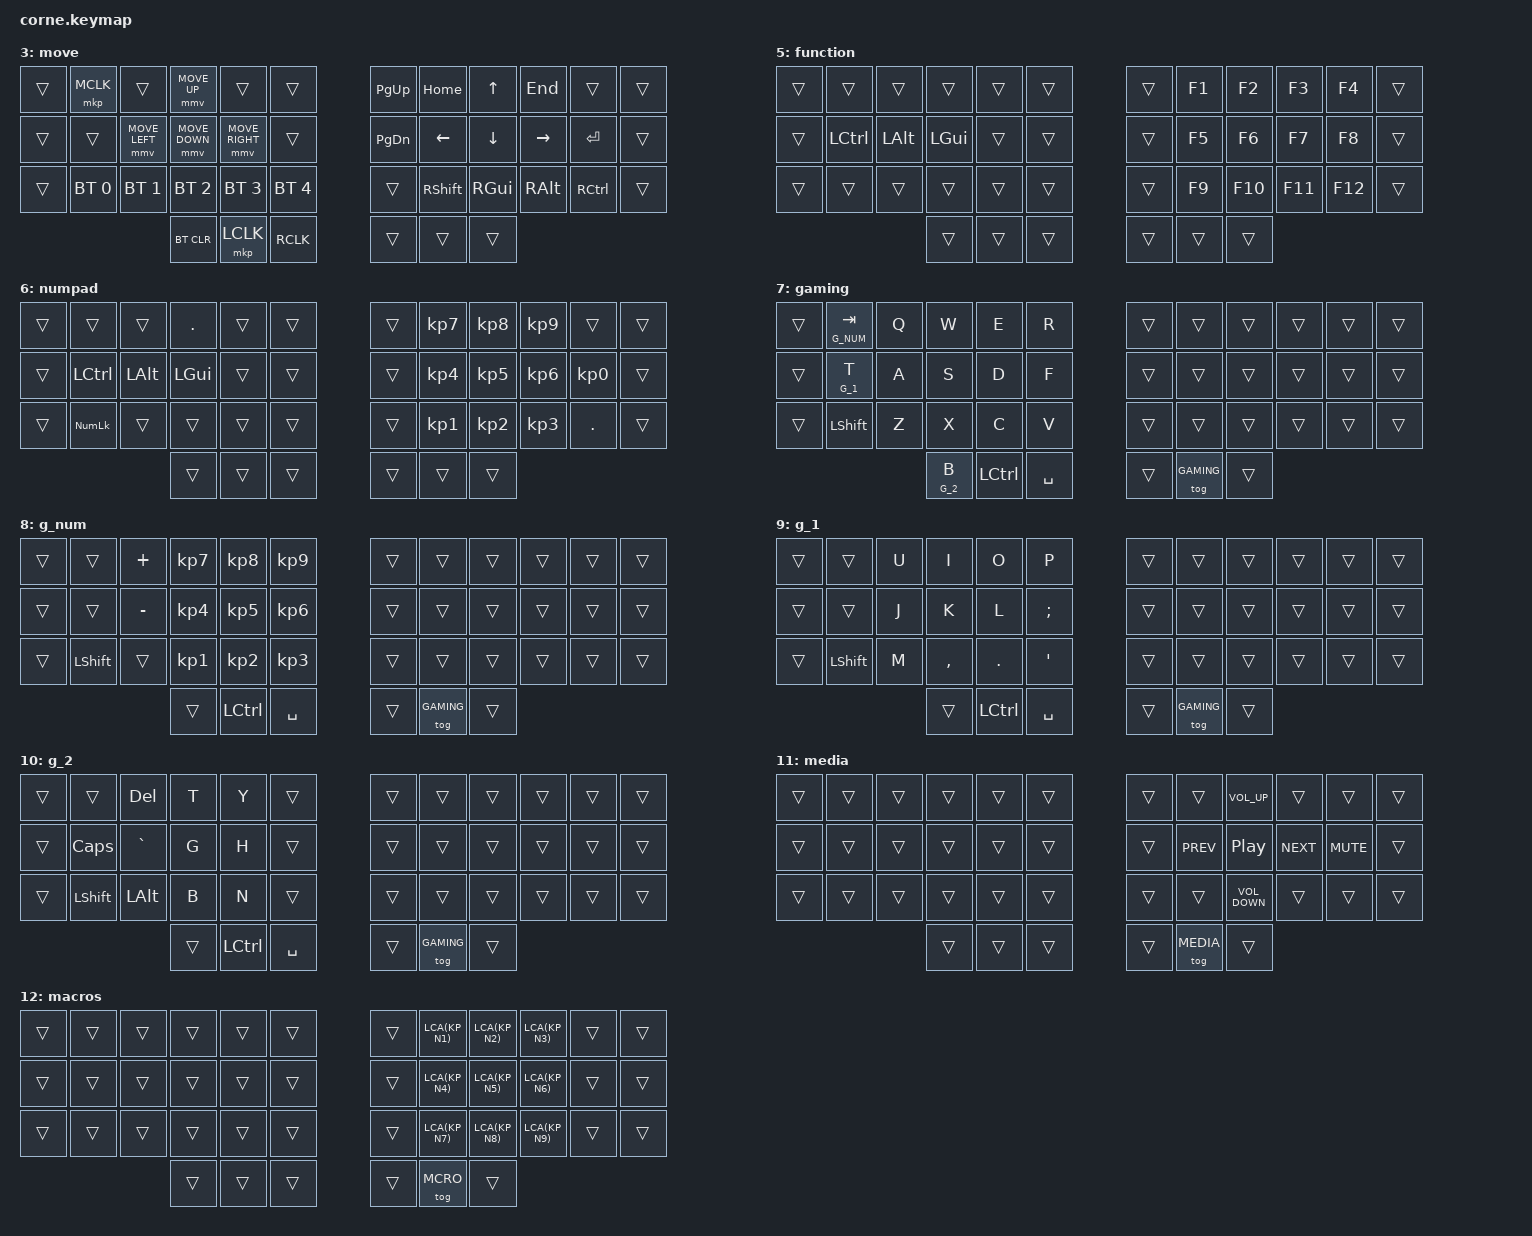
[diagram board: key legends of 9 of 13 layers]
/*
 * Copyright (c) 2020 The ZMK Contributors
 *
 * SPDX-License-Identifier: MIT
 */

#include <behaviors.dtsi>
#include <dt-bindings/zmk/keys.h>
#include <dt-bindings/zmk/bt.h>
#include <dt-bindings/zmk/mouse.h>
/* #include <stdio.h> */
#include "includes/helper.h"
#include "includes/keypos_42keys.h"

#define ___ &trans

// homerow mods
ZMK_BEHAVIOR(hrm, hold_tap,
    flavor = "balanced";
    tapping-term-ms = <280>;
    quick-tap-ms = <125>;
    global-quick-tap;
    bindings = <&kp>, <&kp>;
)

#define LCA(KEY) &kp LC(LA(KEY))

/* Define home row mods */
#define HLC &hrm LCTRL
#define HRC &hrm RCTRL
#define HLA &hrm LALT
#define HRA &hrm RALT
#define HLG &hrm LGUI
#define HRG &hrm RGUI

/* Define shorter mouse keys */
#define MUP &mmv MOVE_UP
#define MDN &mmv MOVE_DOWN
#define MLT &mmv MOVE_LEFT
#define MRT &mmv MOVE_RIGHT
/* clicks */
#define MLC &mkp LCLK
#define MMC &mkp MCLK
#define MRC &kp RCLK

/* Define media controls */ 
#define VUP &kp C_VOLUME_UP
#define VDN &kp C_VOLUME_DOWN
#define VMT &kp C_MUTE
#define PLAY &kp C_PLAY_PAUSE
#define NEXT &kp C_NEXT
#define PREV &kp C_PREV



/*                                      42 KEY MATRIX / LAYOUT MAPPING

  ╭────────────────────────┬────────────────────────╮ ╭─────────────────────────┬─────────────────────────╮
  │ --   1   2   3   4   5 │  6   7   8   9  10  -- │ │ --- LT4 LT3 LT2 LT1 LT0 │ RT0 RT1 RT2 RT3 RT4 --- │
  │ --  13  14  15  16  17 │ 18  19  20  21  22  -- │ │ --- LM4 LM3 LM2 LM1 LM0 │ RM0 RM1 RM2 RM3 RM4 --- │
  │ --  25  26  27  28  29 │ 30  31  32  33  34  -- │ │ --- LB4 LB3 LB2 LB1 LB0 │ RB0 RB1 RB2 RB3 RB4 --- │
  ╰───────────╮ 36  37  38 │ 39  40  41 ╭───────────╯ ╰───────────╮ LH2 LH1 LH0 │ RH0 RH1 RH2 ╭───────────╯
              ╰────────────┴────────────╯                         ╰─────────────┴─────────────╯             */

// layer shortcuts, must match order in which they are defined below
#define DVORAK 0
#define SNTH 1
#define HANDS 2
#define MOV 3
#define SYM 4
#define FUN 5
#define NPD 6
#define GAMING 7
#define G_NUM 8
#define G_1 9
#define G_2 10
#define MEDIA 11
#define MCRO 12

/******************** ALPHA LAYER COMBOS ******************************/ 
// Alpha layout switch
ZMK_COMBO(cb_snth, &to SNTH, RT1 RT2 RT3 , DVORAK HANDS)
ZMK_COMBO(cb_dvorak, &to DVORAK, RM1 RM2 RM3 , SNTH HANDS)
ZMK_COMBO(cb_hands, &to HANDS, RB1 RB2 RB3 , DVORAK SNTH)

// Gaming layer
ZMK_COMBO(cb_game, &to GAMING, LB3 LB2 LB1, DVORAK SNTH HANDS)

// Delete/backspace combos
ZMK_COMBO(cb_delete, &kp DEL, RM0 RT0, DVORAK SNTH HANDS SYM NPD)
ZMK_COMBO(cb_backsp, &kp BSPC, RM1 RT1, SYM NPD)
/* ZMK_COMBO(cb_backsp, &kp BSPC, RM1 RT1, DVORAK SNTH HANDS SYM NPD) */
// Question mark
ZMK_COMBO(cb_question, &kp QMARK, RM2 RT2, DVORAK SNTH HANDS)
ZMK_COMBO(cb_exclamation, &kp EXCL, RM3 RT3, DVORAK SNTH HANDS)
// Tab
ZMK_COMBO(cb_tab, &kp TAB, LM2 LT2, DVORAK SNTH HANDS)
// Esc
ZMK_COMBO(cb_esc, &kp ESC, LM1 LT1, DVORAK SNTH HANDS)
// Forward slash
ZMK_COMBO(cb_forward_slh, &kp FSLH, LM4 LT4, DVORAK SNTH HANDS)
// Caps word
ZMK_COMBO(cb_capsword, &caps_word, LH2 LH1, DVORAK SNTH HANDS)
// F1, F2, F5
ZMK_COMBO(cb_f1, &kp F1, LT4 LT3, DVORAK SNTH HANDS)
ZMK_COMBO(cb_f2, &kp F2, LT3 LT2, DVORAK SNTH HANDS)
ZMK_COMBO(cb_f5, &kp F5, LT2 LT1, DVORAK SNTH HANDS)


/******************** SYMBOL LAYER COMBOS *****************************/ 
ZMK_BEHAVIOR(macro_arrow, macro, // ->
    bindings =  
        <&macro_tap &kp MINUS>, 
        <&macro_tap &kp LS(DOT)>;
)
ZMK_BEHAVIOR(macro_home, macro, // ~/
    bindings =  
        <&macro_tap &kp LS(GRAVE)>,
        <&macro_tap &kp SLASH>;
)
ZMK_COMBO(cb_arrow, &macro_arrow, RM2 RM3, SYM)
ZMK_COMBO(cb_pipe, &kp PIPE, LM4 LM3, SYM)

/******************** GAMING LAYER COMBOS *****************************/ 
ZMK_COMBO(cb_game_esc, &kp ESC, LT1 LT0, GAMING)
ZMK_COMBO(cb_game_bspc, &kp BSPC, LT4 LT3, GAMING)
ZMK_COMBO(cb_game_enter, &kp ENTER, LB2 LB1, GAMING)

/********************* SHIFTED KEY MODS *******************************/ 
// Shifted colon is semicolon
ZMK_BEHAVIOR(cln_semi, mod_morph,
    bindings = <&kp COLON>,  <&kp SEMI> ;
    mods = <(MOD_LSFT|MOD_RSFT)>;
)
/* // Shifted dash is underscore */
ZMK_BEHAVIOR(under_dash, mod_morph,
    bindings = <&kp UNDER>,  <&kp MINUS> ;
    mods = <(MOD_LSFT|MOD_RSFT)>;
)
/* // Shifted tilde is grave */
ZMK_BEHAVIOR(til_de_grave, mod_morph,
    bindings = <&kp TILDE>,  <&kp GRAVE> ;
    mods = <(MOD_LSFT|MOD_RSFT)>;
)

// Shifted question mark is exclamation mark
ZMK_BEHAVIOR(ques_excl, mod_morph,
    bindings = <&kp QMARK>,  <&kp EXCL> ;
    mods = <(MOD_LSFT|MOD_RSFT)>;
)

/********************** COLON MACRO LT ********************************/ 

/* ZMK_BEHAVIOR(lt_colon, hold_tap, */
/*   bindings = <&mo>, <&cln_semi>; */
/* ) */
ZMK_BEHAVIOR(lt_cln, hold_tap,
    flavor = "balanced";
    tapping-term-ms = <280>;
    quick-tap-ms = <125>;
    bindings = <&mo>, <&cln_semi>;
)


/*
  ╭─────────────────────┬────────────────────╮
  │  '   ,   .   p   y  │  f   g   c   r   l │
  │  a   o   e   u   i  │  d   h   t   n   s │
  │  :   q   j   k   x  │  b   m   w   v   z │
  ╰───────╮     sft sym │ ent spc     ╭──────╯
          ╰─────────────┴─────────────╯         */

ZMK_LAYER(dvorak,
     // ╭─────────────┬─────────────┬─────────────┬─────────────┬─────────────╮   ╭─────────────┬─────────────┬─────────────┬─────────────┬─────────────╮
___       &lt NPD SQT    HLC COMMA      HLA DOT       HLG P         &kp Y             &kp F         HRG G         HRA C         HRC R         &kp L        ___ 
     // ├─────────────┼─────────────┼─────────────┼─────────────┼─────────────┤   ├─────────────┼─────────────┼─────────────┼─────────────┼─────────────┤
___          &kp A         &kp O        &kp E         &kp U         &kp I             &kp D         &kp H         &kp T         &kp N         &kp S        ___
     // ├─────────────┼─────────────┼─────────────┼─────────────┼─────────────┤   ├─────────────┼─────────────┼─────────────┼─────────────┼─────────────┤
___     &lt_cln MCRO 0     &kp Q        &kp J         &kp K       &lt FUN X             &kp B         &kp M         &kp W         &kp V         &kp Z        ___
     // ╰─────────────┴─────────────┼─────────────┼─────────────┼─────────────┤   ├─────────────┼─────────────┼─────────────┼─────────────┴─────────────╯
                                       &kp BKSP     &sk LSHIFT     &mo SYM          &lt MOV RET    &kp SPC        &none
     //                             ╰─────────────┴─────────────┴─────────────╯   ╰─────────────┴─────────────┴─────────────╯
)
/*
  ╭─────────────────────┬────────────────────╮
  │  v   p   d   m   "  │bspc  y   o   u   ' │
  │  s   n   r   h   g  │  ,   c   a   e   i │
  │  f   b   j   l   k  │  _   w  ent  .   : │
  ╰───────╮      t  sym │shft spc     ╭──────╯
          ╰─────────────┴─────────────╯         */
ZMK_LAYER(snth,
// ╭─────────────┬────────┬─────────┬────────┬─────────────╮╭─────────────┬─────────────┬─────────────┬─────────────┬─────────────╮
___ &lt NPD V     HLC P     HLA D     HLG M     &kp DQT        &kp BKSP         HRG Y         HRA O         HRC U     &kp SQT   ___ 
// ├─────────────┼────────┼─────────┼────────┼─────────────┤├─────────────┼─────────────┼─────────────┼─────────────┼─────────────┤
___ &kp S         &kp N     &kp R     &kp H     &kp G          &kp COMMA      &kp C         &kp A         &kp E        &kp I       ___
// ├─────────────┼────────┼─────────┼────────┼─────────────┤├─────────────┼─────────────┼─────────────┼─────────────┼─────────────┤
___ &lt MOV F     &kp B     &kp J     &kp L     &lt FUN K      &under_dash     &kp W        &kp RET        &kp DOT    &lt_cln MCRO 0     ___
// ╰─────────────┴────────┼─────────┼────────┼─────────────┤├─────────────┼─────────────┼─────────────┼─────────────┴─────────────╯
                             ___      &kp T      ___         &kp LSHIFT           ___           ___       
//                        ╰─────────┴────────┴─────────────╯╰─────────────┴─────────────┴─────────────╯
)
/*
  ╭─────────────────────┬────────────────────╮
  │  '   b   h   g   "  │  ~   .   j   k   : │
  │  c   s   n   t  ent │  ,   a   e   i   m │
  │  p   f   l   d   v  │  _   u   o   y   w │
  ╰───────╮      r  sym │shft spc     ╭──────╯j
          ╰─────────────┴─────────────╯         */
ZMK_LAYER(hands,
//  ╭─────────────┬─────────┬─────────────┬─────────────┬─────────────╮╭─────────────┬─────────────┬─────────────┬─────────────┬─────────────╮
___  &lt NPD SQT   HLC B        HLA H         HLG G         &kp DQT     &til_de_grave  HRG DOT       HRA J         HRC K         &cln_semi       ___ 
//  ├─────────────┼─────────┼─────────────┼─────────────┼─────────────┤├─────────────┼─────────────┼─────────────┼─────────────┼─────────────┤
___  &kp C         &kp S        &kp N         &kp T       &kp RET       &kp COMMA      &kp A         &kp E         &kp I         &kp M      ___
//  ├─────────────┼─────────┼─────────────┼─────────────┼─────────────┤├─────────────┼─────────────┼─────────────┼─────────────┼─────────────┤
___  &lt MOV P         &kp F        &kp L         &kp D   &lt FUN  V     &under_dash   &kp U         &kp O         &kp Y         &kp W      ___
//  ╰─────────────┴─────────┼─────────────┼─────────────┼─────────────┤├─────────────┼─────────────┼─────────────┼─────────────┴─────────────╯
                                   ___           &kp R           ___       &kp LSHIFT           ___      ___
//                          ╰─────────────┴─────────────┴─────────────╯╰─────────────┴─────────────┴─────────────╯
)

ZMK_LAYER(move,
     // ╭─────────────┬─────────────┬─────────────┬─────────────┬─────────────╮   ╭─────────────┬─────────────┬─────────────┬─────────────┬─────────────╮
___            MMC          ___           MUP          ___            ___            &kp PG_UP      &kp HOME      &kp UP        &kp END         ___         ___
     // ├─────────────┼─────────────┼─────────────┼─────────────┼─────────────┤   ├─────────────┼─────────────┼─────────────┼─────────────┼─────────────┤
___           ___           MLT           MDN          MRT            ___            &kp PG_DN      &kp LEFT     &kp DOWN      &kp RIGHT     &kp RET        ___
     // ├─────────────┼─────────────┼─────────────┼─────────────┼─────────────┤   ├─────────────┼─────────────┼─────────────┼─────────────┼─────────────┤
___      &bt BT_SEL 0   &bt BT_SEL 1  &bt BT_SEL 2  &bt BT_SEL 3  &bt BT_SEL 4         ___         &kp RSHIFT    &kp RGUI      &kp RALT     &kp RCTRL       ___
     // ╰─────────────┴─────────────┼─────────────┼─────────────┼─────────────┤   ├─────────────┼─────────────┼─────────────┼─────────────┴─────────────╯
                                      &bt BT_CLR       MLC            MRC              ___           ___            ___
     //                             ╰─────────────┴─────────────┴─────────────╯   ╰─────────────┴─────────────┴─────────────╯
)
/*
  ╭─────────────────────┬────────────────────╮
  │      @   #   $   ~/ │      [   ]   %  q  │
  │  /   \   _   *   `  │  +   {   }   -  =  │
  │              ^      │  x   (   )   &  z  │
  ╰───────╮     sft sym │ ent spc     ╭──────╯
          ╰─────────────┴─────────────╯         */
ZMK_LAYER(symbols,
     // ╭──────────────┬───────────────┬───────────────┬─────────────┬─────────────╮   ╭─────────────┬─────────────┬─────────────┬─────────────┬─────────────╮
___         &sl MEDIA      &kp AT           &kp HASH       &kp DLLR    &macro_home       &kp BSPC       &kp LBKT      &kp RBKT      &kp PRCNT       &kp Q        ___
     // ├──────────────┼───────────────┼───────────────┼─────────────┼─────────────┤   ├─────────────┼─────────────┼─────────────┼─────────────┼─────────────┤
___         HLC FSLH       HLA BSLH        HLG UNDER       &kp STAR     &kp GRAVE         &kp PLUS      &kp LBRC      HRG RBRC      HRA MINUS     HRC EQUAL    ___ 
     // ├──────────────┼───────────────┼───────────────┼─────────────┼─────────────┤   ├─────────────┼─────────────┼─────────────┼─────────────┼─────────────┤
___           ___            ___               ___        &kp CARET        ___             &kp X        &kp LPAR      &kp RPAR       &kp AMPS       &kp Z       ___
     // ╰──────────────┴───────────────┼───────────────┼─────────────┼─────────────┤   ├─────────────┼─────────────┼─────────────┼─────────────┴─────────────╯
                                               ___           ___           ___             ___          &kp TAB         ___
     //                                ╰───────────────┴─────────────┴─────────────╯   ╰─────────────┴─────────────┴─────────────╯
)
/*
  ╭─────────────────────┬────────────────────╮
  │                     │    F1  F2  F3  F4  │
  │                     │    F5  F6  F7  F7  │
  │                     │    F9  F10 F11 F12 │
  ╰───────╮             │             ╭──────╯
          ╰─────────────┴─────────────╯         */
ZMK_LAYER(function,
     // ╭──────────────┬───────────────┬───────────────┬─────────────┬───────────╮   ╭─────────────┬─────────────┬─────────────┬─────────────┬─────────────╮
___           ___             ___             ___            ___          ___              ___         &kp F1         &kp F2        &kp F3       &kp F4       ___
     // ├──────────────┼───────────────┼───────────────┼─────────────┼───────────┤   ├─────────────┼─────────────┼─────────────┼─────────────┼─────────────┤
___        &kp LCTRL       &kp LALT         &kp LGUI         ___          ___              ___         &kp F5         &kp F6        &kp F7       &kp F8       ___
     // ├──────────────┼───────────────┼───────────────┼─────────────┼───────────┤   ├─────────────┼─────────────┼─────────────┼─────────────┼─────────────┤
___           ___             ___             ___            ___          ___              ___         &kp F9        &kp F10       &kp F11      &kp F12       ___
     // ╰──────────────┴───────────────┼───────────────┼─────────────┼───────────┤   ├─────────────┼─────────────┼─────────────┼─────────────┴─────────────╯
                                             ___             ___          ___              ___           ___           ___
     //                                ╰───────────────┴─────────────┴───────────╯   ╰─────────────┴─────────────┴─────────────╯
)
/*
  ╭─────────────────────┬────────────────────╮
  │          .          │      7   8   9     │
  │                     │      4   5   6  0  │
  │numlock              │      1   2   3     │
  ╰───────╮             │             ╭──────╯
          ╰─────────────┴─────────────╯         */
ZMK_LAYER(numpad,
     // ╭──────────────┬───────────────┬───────────────┬─────────────┬───────────╮   ╭─────────────┬─────────────┬─────────────┬─────────────┬─────────────╮
___           ___             ___          &kp DOT            ___          ___              ___       &kp KP_N7     &kp KP_N8      &kp KP_N9       ___        ___
     // ├──────────────┼───────────────┼───────────────┼─────────────┼───────────┤   ├─────────────┼─────────────┼─────────────┼─────────────┼─────────────┤
___        &kp LCTRL       &kp LALT         &kp LGUI         ___          ___              ___        &kp KP_N4     &kp KP_N5      &kp KP_N6    &kp KP_N0     ___
     // ├──────────────┼───────────────┼───────────────┼─────────────┼───────────┤   ├─────────────┼─────────────┼─────────────┼─────────────┼─────────────┤
___       &kp KP_NLCK         ___             ___            ___          ___              ___        &kp KP_N1     &kp KP_N2      &kp KP_N3    &kp DOT       ___
     // ╰──────────────┴───────────────┼───────────────┼─────────────┼───────────┤   ├─────────────┼─────────────┼─────────────┼─────────────┴─────────────╯
                                             ___             ___          ___              ___           ___           ___
     //                                ╰───────────────┴─────────────┴───────────╯   ╰─────────────┴─────────────┴─────────────╯
)
/*
  ╭─────────────────────┬────────────────────╮
  │ tab q   w   e   r   │                    │
  │  t  a   s   d   f   │                    │
  │shft z   x   c   v   │                    │
  ╰───────╮ b ctrl spc  │             ╭──────╯
          ╰─────────────┴─────────────╯         */
ZMK_LAYER(gaming,
     // ╭──────────────┬───────────────┬───────────────┬─────────────┬───────────╮   ╭─────────────┬─────────────┬─────────────┬─────────────┬─────────────╮
___       &lt G_NUM TAB     &kp Q           &kp W           &kp E        &kp R             ___           ___           ___           ___           ___       ___
     // ├──────────────┼───────────────┼───────────────┼─────────────┼───────────┤   ├─────────────┼─────────────┼─────────────┼─────────────┼─────────────┤
___        &lt G_1 T        &kp A           &kp S           &kp D        &kp F             ___           ___           ___           ___           ___       ___
     // ├──────────────┼───────────────┼───────────────┼─────────────┼───────────┤   ├─────────────┼─────────────┼─────────────┼─────────────┼─────────────┤
___        &kp LSHIFT       &kp Z           &kp X           &kp C        &kp V             ___           ___           ___           ___           ___       ___
     // ╰──────────────┴───────────────┼───────────────┼─────────────┼───────────┤   ├─────────────┼─────────────┼─────────────┼─────────────┴─────────────╯
                                           &lt G_2 B      &kp LCTRL     &kp SPC            ___       &tog GAMING       ___
     //                                ╰───────────────┴─────────────┴───────────╯   ╰─────────────┴─────────────┴─────────────╯
)
/*
  ╭─────────────────────┬────────────────────╮
  │      +  7   8   9   │                    │
  │      -  4   5   6   │                    │
  │shft     1   2   3   │                    │
  ╰───────╮   ctrl spc  │             ╭──────╯
          ╰─────────────┴─────────────╯         */
ZMK_LAYER(g_num,
     // ╭──────────────┬───────────────┬───────────────┬─────────────┬───────────╮   ╭─────────────┬─────────────┬─────────────┬─────────────┬─────────────╮
___           ___          &kp PLUS       &kp KP_N7      &kp KP_N8     &kp KP_N9             ___           ___           ___           ___           ___       ___
     // ├──────────────┼───────────────┼───────────────┼─────────────┼───────────┤   ├─────────────┼─────────────┼─────────────┼─────────────┼─────────────┤
___           ___          &kp MINUS      &kp KP_N4      &kp KP_N5     &kp KP_N6             ___           ___           ___           ___           ___       ___
     // ├──────────────┼───────────────┼───────────────┼─────────────┼───────────┤   ├─────────────┼─────────────┼─────────────┼─────────────┼─────────────┤
___        &kp LSHIFT        ___          &kp KP_N1      &kp KP_N2     &kp KP_N3             ___           ___           ___           ___           ___       ___
     // ╰──────────────┴───────────────┼───────────────┼─────────────┼───────────┤   ├─────────────┼─────────────┼─────────────┼─────────────┴─────────────╯
                                             ___          &kp LCTRL     &kp SPC            ___       &tog GAMING       ___
     //                                ╰───────────────┴─────────────┴───────────╯   ╰─────────────┴─────────────┴─────────────╯
)
/*
  ╭─────────────────────┬────────────────────╮
  │      u  i   o   p   │                    │
  │      j  k   l   ;   │                    │
  │shft  m  ,   .   '   │                    │
  ╰───────╮   ctrl spc  │             ╭──────╯
          ╰─────────────┴─────────────╯         */
ZMK_LAYER(g_1,
     // ╭──────────────┬───────────────┬───────────────┬─────────────┬───────────╮   ╭─────────────┬─────────────┬─────────────┬─────────────┬─────────────╮
___           ___           &kp U           &kp I          &kp O         &kp P              ___           ___           ___           ___           ___       ___
     // ├──────────────┼───────────────┼───────────────┼─────────────┼───────────┤   ├─────────────┼─────────────┼─────────────┼─────────────┼─────────────┤
___           ___           &kp J           &kp K          &kp L       &kp SEMI             ___           ___           ___           ___           ___       ___
     // ├──────────────┼───────────────┼───────────────┼─────────────┼───────────┤   ├─────────────┼─────────────┼─────────────┼─────────────┼─────────────┤
___        &kp LSHIFT       &kp M          &kp COMMA       &kp DOT     &kp SQT              ___           ___           ___           ___           ___       ___
     // ╰──────────────┴───────────────┼───────────────┼─────────────┼───────────┤   ├─────────────┼─────────────┼─────────────┼─────────────┴─────────────╯
                                             ___          &kp LCTRL    &kp SPC              ___       &tog GAMING       ___
     //                                ╰───────────────┴─────────────┴───────────╯   ╰─────────────┴─────────────┴─────────────╯
)
/*
  ╭─────────────────────┬────────────────────╮
  │     del t   o       │                    │
  │      ~  g   h       │                    │
  │shft alt b   n       │                    │
  ╰───────╮   ctrl spc  │             ╭──────╯
          ╰─────────────┴─────────────╯         */
ZMK_LAYER(g_2,
     // ╭──────────────┬───────────────┬───────────────┬─────────────┬───────────╮   ╭─────────────┬─────────────┬─────────────┬─────────────┬─────────────╮
___           ___         &kp DEL           &kp T          &kp Y          ___               ___           ___           ___           ___           ___       ___
     // ├──────────────┼───────────────┼───────────────┼─────────────┼───────────┤   ├─────────────┼─────────────┼─────────────┼─────────────┼─────────────┤
___         &kp CAPS      &kp GRAVE         &kp G          &kp H          ___               ___           ___           ___           ___           ___       ___
     // ├──────────────┼───────────────┼───────────────┼─────────────┼───────────┤   ├─────────────┼─────────────┼─────────────┼─────────────┼─────────────┤
___        &kp LSHIFT     &kp LALT          &kp B          &kp N          ___               ___           ___           ___           ___           ___       ___
     // ╰──────────────┴───────────────┼───────────────┼─────────────┼───────────┤   ├─────────────┼─────────────┼─────────────┼─────────────┴─────────────╯
                                             ___          &kp LCTRL    &kp SPC              ___       &tog GAMING       ___
     //                                ╰───────────────┴─────────────┴───────────╯   ╰─────────────┴─────────────┴─────────────╯
)
ZMK_LAYER(media,
     // ╭──────────────┬───────────────┬───────────────┬─────────────┬───────────╮   ╭─────────────┬─────────────┬─────────────┬─────────────┬─────────────╮
___           ___             ___             ___            ___          ___              ___           ___           VUP           ___           ___       ___
     // ├──────────────┼───────────────┼───────────────┼─────────────┼───────────┤   ├─────────────┼─────────────┼─────────────┼─────────────┼─────────────┤
___           ___             ___             ___            ___          ___              ___          PREV           PLAY          NEXT          VMT       ___
     // ├──────────────┼───────────────┼───────────────┼─────────────┼───────────┤   ├─────────────┼─────────────┼─────────────┼─────────────┼─────────────┤
___           ___             ___             ___            ___          ___              ___           ___           VDN           ___           ___       ___
     // ╰──────────────┴───────────────┼───────────────┼─────────────┼───────────┤   ├─────────────┼─────────────┼─────────────┼─────────────┴─────────────╯
                                              ___             ___          ___             ___        &tog MEDIA       ___
     //                                ╰───────────────┴─────────────┴───────────╯   ╰─────────────┴─────────────┴─────────────╯
)
ZMK_LAYER(macros,
     // ╭──────────────┬───────────────┬───────────────┬─────────────┬───────────╮   ╭─────────────┬─────────────┬─────────────┬─────────────┬─────────────╮
___           ___             ___             ___            ___          ___              ___        LCA(KP_N1)   LCA(KP_N2)    LCA(KP_N3)        ___       ___
     // ├──────────────┼───────────────┼───────────────┼─────────────┼───────────┤   ├─────────────┼─────────────┼─────────────┼─────────────┼─────────────┤
___           ___             ___             ___            ___          ___              ___        LCA(KP_N4)   LCA(KP_N5)    LCA(KP_N6)        ___       ___
     // ├──────────────┼───────────────┼───────────────┼─────────────┼───────────┤   ├─────────────┼─────────────┼─────────────┼─────────────┼─────────────┤
___           ___             ___             ___            ___          ___              ___        LCA(KP_N7)   LCA(KP_N8)    LCA(KP_N9)        ___       ___
     // ╰──────────────┴───────────────┼───────────────┼─────────────┼───────────┤   ├─────────────┼─────────────┼─────────────┼─────────────┴─────────────╯
                                             ___             ___          ___              ___        &tog MCRO       ___
     //                                ╰───────────────┴─────────────┴───────────╯   ╰─────────────┴─────────────┴─────────────╯
)
/* ZMK_LAYER(media, */
/*      // ╭──────────────┬───────────────┬───────────────┬─────────────┬───────────╮   ╭─────────────┬─────────────┬─────────────┬─────────────┬─────────────╮ */
/* ___           ___             ___             ___            ___          ___              ___           ___           ___           ___           ___       ___ */
/*      // ├──────────────┼───────────────┼───────────────┼─────────────┼───────────┤   ├─────────────┼─────────────┼─────────────┼─────────────┼─────────────┤ */
/* ___           ___             ___             ___            ___          ___              ___           ___           ___           ___           ___       ___ */
/*      // ├──────────────┼───────────────┼───────────────┼─────────────┼───────────┤   ├─────────────┼─────────────┼─────────────┼─────────────┼─────────────┤ */
/* ___           ___             ___             ___            ___          ___              ___           ___           ___           ___           ___       ___ */
/*      // ╰──────────────┴───────────────┼───────────────┼─────────────┼───────────┤   ├─────────────┼─────────────┼─────────────┼─────────────┴─────────────╯ */
/*                                              ___             ___          ___              ___          &tog <<LAYER>>          ___ */
/*      //                                ╰───────────────┴─────────────┴───────────╯   ╰─────────────┴─────────────┴─────────────╯ */
/* ) */
